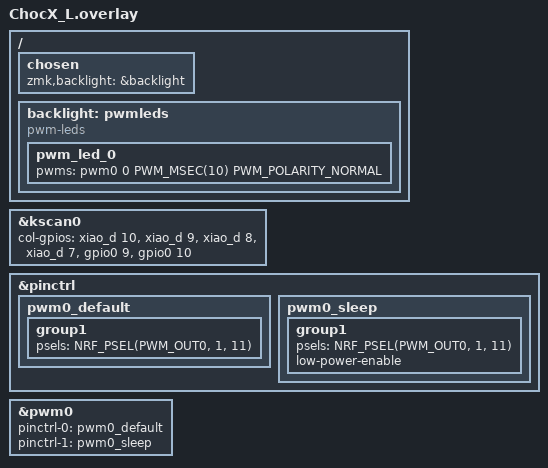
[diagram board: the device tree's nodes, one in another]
#include "ChocX.dtsi"

&kscan0 {
        col-gpios
            = <&xiao_d 10 GPIO_ACTIVE_HIGH>
            , <&xiao_d 9 GPIO_ACTIVE_HIGH> 
            , <&xiao_d 8 GPIO_ACTIVE_HIGH> 
            , <&xiao_d 7 GPIO_ACTIVE_HIGH> 
            , <&gpio0 9 GPIO_ACTIVE_HIGH>
            , <&gpio0 10 GPIO_ACTIVE_HIGH>
            ;
};

&pinctrl {
    // Other pinctrl definitions for other hardware
    pwm0_default: pwm0_default {
        group1 {
            psels = <NRF_PSEL(PWM_OUT0, 1, 11)>;
        };
    };
    pwm0_sleep: pwm0_sleep {
        group1 {
            psels = <NRF_PSEL(PWM_OUT0, 1, 11)>;
            low-power-enable;
        };
    };
};

&pwm0 {
    status = "okay";
    pinctrl-0 = <&pwm0_default>;
    pinctrl-1 = <&pwm0_sleep>;
    pinctrl-names = "default", "sleep";
};

/ {
    chosen {
        zmk,backlight = &backlight;
    };

    backlight: pwmleds {
        compatible = "pwm-leds";
        pwm_led_0 {
            pwms = <&pwm0 0 PWM_MSEC(10) PWM_POLARITY_NORMAL>;
        };
    };
};
